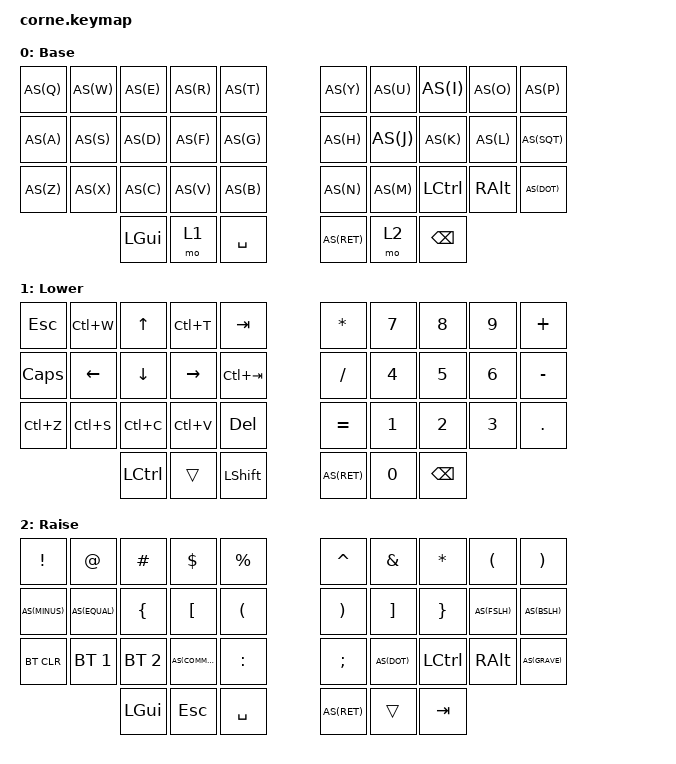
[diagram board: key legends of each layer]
/*
 * Copyright (c) 2020 The ZMK Contributors
 *
 * SPDX-License-Identifier: MIT
 */

#include <behaviors.dtsi>
#include <dt-bindings/zmk/keys.h>
#include <dt-bindings/zmk/bt.h>


#define AS(keycode) &as LS(keycode) keycode

/ {
    chosen {
      zmk,matrix_transform = &five_column_transform;
    };
     combos {
        compatible = "zmk,combos";

        screenshot {
            bindings = <&kp LG(LS(S))>;
            key-positions = <11 12 13 31>; 
        };
        TaskManager {
            bindings = <&kp LC(LS(ESCAPE))>;
            key-positions = <0 10 20 31>;
        };
    };
    behaviors {
        ShiftSelect: ShiftSelect {
            compatible = "zmk,behavior-caps-word";
            label = "SHIFTSELECT";
            #binding-cells = <0>;
            mods = <(MOD_LSFT)>;
            continue-list = <LEFT_ARROW DOWN_ARROW RIGHT_ARROW UP_ARROW UP RIGHT DOWN LEFT>;
        };
        as: auto_shift {
            compatible = "zmk,behavior-hold-tap";
            #binding-cells = <2>;
            tapping_term_ms = <300>;
            quick_tap_ms = <0>;
            flavor = "tap-preferred";
            bindings = <&kp>, <&kp>;
        };
    };
        keymap {
                compatible = "zmk,keymap";

                default_layer {
// -----------------------------------------------------------------------------------------
// |  Q  |  W  |  E  |  R  |  T  |     |  Y  |  U   |  I   |  O   | P |
// |  A  |  S  |  D  |  F  |  G  |     |  H  |  J   |  K   |  L   | ' | 
// |  Z  |  X  |  C  |  V  |  B  |     |  N  |  M   | CTRL | META | . |           
//             | GUI | LWR | SPC |     | ENT | RSE  | BSPC |
                        display-name = "Base";
                        bindings = <
   AS(Q) AS(W) AS(E) AS(R) AS(T)     AS(Y)   AS(U)  AS(I)     AS(O)     AS(P)
   AS(A) AS(S) AS(D) AS(F) AS(G)     AS(H)   AS(J)  AS(K)     AS(L)     AS(SQT)
   AS(Z) AS(X) AS(C) AS(V) AS(B)     AS(N)   AS(M)  &kp LCTL  &kp RALT  AS(DOT)
        &kp LGUI &mo 1 &kp SPACE     AS(RET) &mo 2  &kp BSPC
                        >;
                };

                lower_layer {
// -----------------------------------------------------------------------------------------
// | ESCAPE    |  CNTRL-W |  UP     | CNTRL-T | TAB     |     | *   | 7   | 8   | 9   | +   |
// | CAPS-LOCK |  LEFT    | DOWN    | RIGHT   | ALT-TAB |     | /   | 4   | 5   | 6   | -   |
// | CNTRL-Z   |  CNTRL-S | CNTRL-C | CNTRL-V | DELETE  |     | =   | 1   | 2   | 3   | .   |
//                                    | CTRL |     | SHIFT |     | ENT | 0   | BSPC |
                        display-name = "Lower";
                        bindings = <
   &kp ESCAPE    &kp LC(W)     &kp UP       &kp LC(T)      &kp TAB                &kp ASTERISK   &kp NUMBER_7  &kp NUMBER_8  &kp NUMBER_9  &kp PLUS
   &kp CAPSLOCK  &kp LEFT      &kp DOWN     &kp RIGHT      &kp LC(TAB)            &kp SLASH      &kp NUMBER_4  &kp NUMBER_5  &kp NUMBER_6  &kp MINUS 
   &kp LC(Z)     &kp LC(S)     &kp LC(C)    &kp LC(V)      &kp DELETE             &kp EQUAL    &kp NUMBER_1  &kp NUMBER_2  &kp NUMBER_3  &kp DOT 
                               &kp LCTL     &trans       &kp LSHIFT                 AS(RET)   &kp NUMBER_0   &kp BSPC
                        >;
                };

                raise_layer {
// -----------------------------------------------------------------------------------------
// | !    |  @   |  #   |  $ |  % |         |  ^  |  &  |  *  |  (   |  )   |
// | -_    |  =+    |  {  |  [  |  (  |     |  )  |  ]  |  }  |  /?  |  \|  |
// | BTCLR | BT1    |  BT2   |  ,< |  :  |     |  ;  |  .> | CTRL| META |  `~     |
//            | GUI | ESC | SPC |     | ENT |     | TAB |
                        display-name = "Raise";
                        bindings = <

   &kp EXCLAMATION  &kp AT_SIGN  &kp HASH        &kp DOLLAR   &kp PERCENT &kp CARET   &kp AMPERSAND &kp ASTERISK &kp LEFT_PARENTHESIS &kp RIGHT_PARENTHESIS
   AS(MINUS)        AS(EQUAL)    &kp LBRC        &kp LBKT     &kp LPAR    &kp RPAR    &kp RBKT      &kp RBRC     AS(FSLH)             AS(BSLH)
   &bt BT_CLR       &bt BT_SEL 1 &bt BT_SEL 2    AS(COMMA)    &kp COLON   &kp SEMI    AS(DOT)       &kp LCTRL    &kp RALT             AS(GRAVE)
                       &kp LGUI  &kp ESC   &kp SPACE     AS(RET)   &trans    &kp TAB
                        >;
                };
        };
};
